AUTOSAR XML (schema 4-2-2)
package /Components
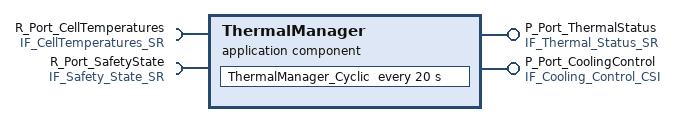
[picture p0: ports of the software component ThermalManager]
  application sw component type ThermalManager
    provide port P_Port_ThermalStatus: provided-interface=IF_Thermal_Status_SR
    provide port P_Port_CoolingControl: provided-interface=IF_Cooling_Control_CSI
    require port R_Port_CellTemperatures: required-interface=IF_CellTemperatures_SR
    require port R_Port_SafetyState: required-interface=IF_Safety_State_SR
    behavior ThermalManager_InternalBehavior
      init event ThermalManager_Init_Event: start-on-event=ThermalManager_Init
      operation invoked event Cooling_SetPumpSpeed_Invoked: start-on-event=ThermalManager_Handle_SetPump
      operation invoked event Cooling_SetFanSpeed_Invoked: start-on-event=ThermalManager_Handle_SetFan
      timing event ThermalManager_20ms_Event: start-on-event=ThermalManager_Cyclic, period=20
      4 x runnable:
        ThermalManager_Init
          data-send-points:
            access VA_Init_CoolantPumpSpeed: accessed-variable=P_Port_ThermalStatus.CoolantPumpSpeed
            access VA_Init_FanSpeed: accessed-variable=P_Port_ThermalStatus.FanSpeed
            access VA_Init_ThermalFault: accessed-variable=P_Port_ThermalStatus.ThermalFault
        ThermalManager_Cyclic: minimum-start-interval=20
          data-receive-point-by-values:
            4 x access:
              VA_Cyc_CellTemperatures_Array: accessed-variable=R_Port_CellTemperatures.CellTemperatures_Array
              VA_Cyc_PackTemperature: accessed-variable=R_Port_CellTemperatures.PackTemperature
              VA_Cyc_SafetyState: accessed-variable=R_Port_SafetyState.SafetyState
              VA_Cyc_FaultCode: accessed-variable=R_Port_SafetyState.FaultCode
          data-send-points:
            access VA_Cyc_CoolantPumpSpeed: accessed-variable=P_Port_ThermalStatus.CoolantPumpSpeed
            access VA_Cyc_FanSpeed: accessed-variable=P_Port_ThermalStatus.FanSpeed
            access VA_Cyc_ThermalFault: accessed-variable=P_Port_ThermalStatus.ThermalFault
        ThermalManager_Handle_SetPump
          data-receive-point-by-arguments:
            access VA_Handle_SetPump_Arg_CoolantPumpSpeed: accessed-variable=P_Port_CoolingControl.CoolantPumpSpeed
        ThermalManager_Handle_SetFan
          data-receive-point-by-arguments:
            access VA_Handle_SetFan_Arg_FanSpeed: accessed-variable=P_Port_CoolingControl.FanSpeed
